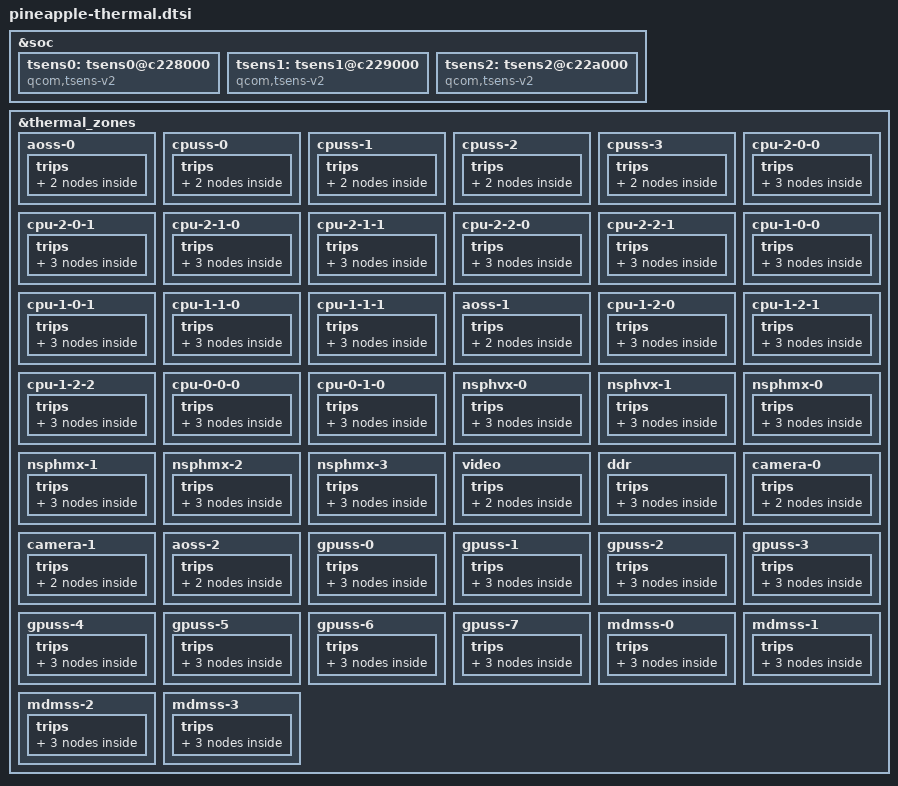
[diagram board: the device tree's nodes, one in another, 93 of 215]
#include <dt-bindings/thermal/thermal_qti.h>

&soc {
	tsens0: tsens0@c228000 {
		compatible = "qcom,tsens-v2";
		reg = <0x0c228000 0x1ff>, /* TM */
		      <0x0c222000 0x1ff>; /* SROT */
		#qcom,sensors = <15>;
		interrupts = <GIC_SPI 506 IRQ_TYPE_LEVEL_HIGH>,
			     <GIC_SPI 640 IRQ_TYPE_LEVEL_HIGH>;
		interrupt-names = "uplow","critical";
		#thermal-sensor-cells = <1>;
	};

	tsens1: tsens1@c229000 {
		compatible = "qcom,tsens-v2";
		reg = <0x0c229000 0x1ff>, /* TM */
		      <0x0c223000 0x1ff>; /* SROT */
		#qcom,sensors = <16>;
		interrupts = <GIC_SPI 507 IRQ_TYPE_LEVEL_HIGH>,
			     <GIC_SPI 641 IRQ_TYPE_LEVEL_HIGH>;
		interrupt-names = "uplow","critical";
		#thermal-sensor-cells = <1>;
	};

	tsens2: tsens2@c22a000 {
		compatible = "qcom,tsens-v2";
		reg = <0x0c22a000 0x1ff>, /* TM */
		      <0x0c224000 0x1ff>; /* SROT */
		#qcom,sensors = <13>;
		interrupts = <GIC_SPI 508 IRQ_TYPE_LEVEL_HIGH>,
			     <GIC_SPI 642 IRQ_TYPE_LEVEL_HIGH>;
		interrupt-names = "uplow","critical";
		#thermal-sensor-cells = <1>;
	};
};

&thermal_zones {
	aoss-0 {
		polling-delay-passive = <0>;
		polling-delay = <0>;
		thermal-sensors = <&tsens0 0>;
		trips {
			thermal-engine-config {
				temperature = <125000>;
				hysteresis = <1000>;
				type = "passive";
			};

			reset-mon-cfg {
				temperature = <115000>;
				hysteresis = <5000>;
				type = "passive";
			};
		};
	};

	cpuss-0 {
		polling-delay-passive = <0>;
		polling-delay = <0>;
		thermal-sensors = <&tsens0 1>;
		trips {
			thermal-engine-config {
				temperature = <125000>;
				hysteresis = <1000>;
				type = "passive";
			};

			reset-mon-cfg {
				temperature = <115000>;
				hysteresis = <5000>;
				type = "passive";
			};
		};
	};

	cpuss-1 {
		polling-delay-passive = <0>;
		polling-delay = <0>;
		thermal-sensors = <&tsens0 2>;
		trips {
			thermal-engine-config {
				temperature = <125000>;
				hysteresis = <1000>;
				type = "passive";
			};

			reset-mon-cfg {
				temperature = <115000>;
				hysteresis = <5000>;
				type = "passive";
			};
		};
	};

	cpuss-2 {
		polling-delay-passive = <0>;
		polling-delay = <0>;
		thermal-sensors = <&tsens0 3>;
		trips {
			thermal-engine-config {
				temperature = <125000>;
				hysteresis = <1000>;
				type = "passive";
			};

			reset-mon-cfg {
				temperature = <115000>;
				hysteresis = <5000>;
				type = "passive";
			};
		};
	};

	cpuss-3 {
		polling-delay-passive = <0>;
		polling-delay = <0>;
		thermal-sensors = <&tsens0 4>;
		trips {
			thermal-engine-config {
				temperature = <125000>;
				hysteresis = <1000>;
				type = "passive";
			};

			reset-mon-cfg {
				temperature = <115000>;
				hysteresis = <5000>;
				type = "passive";
			};
		};
	};

	cpu-2-0-0 {
		polling-delay-passive = <0>;
		polling-delay = <0>;
		thermal-sensors = <&tsens0 5>;
		trips {
			thermal-engine-config {
				temperature = <125000>;
				hysteresis = <1000>;
				type = "passive";
			};

			thermal-hal-config {
				temperature = <125000>;
				hysteresis = <1000>;
				type = "passive";
			};

			reset-mon-cfg {
				temperature = <115000>;
				hysteresis = <5000>;
				type = "passive";
			};
		};
	};

	cpu-2-0-1 {
		polling-delay-passive = <0>;
		polling-delay = <0>;
		thermal-sensors = <&tsens0 6>;
		trips {
			thermal-engine-config {
				temperature = <125000>;
				hysteresis = <1000>;
				type = "passive";
			};

			thermal-hal-config {
				temperature = <125000>;
				hysteresis = <1000>;
				type = "passive";
			};

			reset-mon-cfg {
				temperature = <115000>;
				hysteresis = <5000>;
				type = "passive";
			};
		};
	};

	cpu-2-1-0 {
		polling-delay-passive = <0>;
		polling-delay = <0>;
		thermal-sensors = <&tsens0 7>;
		trips {
			thermal-engine-config {
				temperature = <125000>;
				hysteresis = <1000>;
				type = "passive";
			};

			thermal-hal-config {
				temperature = <125000>;
				hysteresis = <1000>;
				type = "passive";
			};

			reset-mon-cfg {
				temperature = <115000>;
				hysteresis = <5000>;
				type = "passive";
			};
		};
	};

	cpu-2-1-1 {
		polling-delay-passive = <0>;
		polling-delay = <0>;
		thermal-sensors = <&tsens0 8>;
		trips {
			thermal-engine-config {
				temperature = <125000>;
				hysteresis = <1000>;
				type = "passive";
			};

			thermal-hal-config {
				temperature = <125000>;
				hysteresis = <1000>;
				type = "passive";
			};

			reset-mon-cfg {
				temperature = <115000>;
				hysteresis = <5000>;
				type = "passive";
			};
		};
	};

	cpu-2-2-0 {
		polling-delay-passive = <0>;
		polling-delay = <0>;
		thermal-sensors = <&tsens0 9>;
		trips {
			thermal-engine-config {
				temperature = <125000>;
				hysteresis = <1000>;
				type = "passive";
			};

			thermal-hal-config {
				temperature = <125000>;
				hysteresis = <1000>;
				type = "passive";
			};

			reset-mon-cfg {
				temperature = <115000>;
				hysteresis = <5000>;
				type = "passive";
			};
		};
	};

	cpu-2-2-1 {
		polling-delay-passive = <0>;
		polling-delay = <0>;
		thermal-sensors = <&tsens0 10>;
		trips {
			thermal-engine-config {
				temperature = <125000>;
				hysteresis = <1000>;
				type = "passive";
			};

			thermal-hal-config {
				temperature = <125000>;
				hysteresis = <1000>;
				type = "passive";
			};

			reset-mon-cfg {
				temperature = <115000>;
				hysteresis = <5000>;
				type = "passive";
			};
		};
	};

	cpu-1-0-0 {
		polling-delay-passive = <0>;
		polling-delay = <0>;
		thermal-sensors = <&tsens0 11>;
		trips {
			thermal-engine-config {
				temperature = <125000>;
				hysteresis = <1000>;
				type = "passive";
			};

			thermal-hal-config {
				temperature = <125000>;
				hysteresis = <1000>;
				type = "passive";
			};

			reset-mon-cfg {
				temperature = <115000>;
				hysteresis = <5000>;
				type = "passive";
			};
		};
	};

	cpu-1-0-1 {
		polling-delay-passive = <0>;
		polling-delay = <0>;
		thermal-sensors = <&tsens0 12>;
		trips {
			thermal-engine-config {
				temperature = <125000>;
				hysteresis = <1000>;
				type = "passive";
			};

			thermal-hal-config {
				temperature = <125000>;
				hysteresis = <1000>;
				type = "passive";
			};

			reset-mon-cfg {
				temperature = <115000>;
				hysteresis = <5000>;
				type = "passive";
			};
		};
	};

	cpu-1-1-0 {
		polling-delay-passive = <0>;
		polling-delay = <0>;
		thermal-sensors = <&tsens0 13>;
		trips {
			thermal-engine-config {
				temperature = <125000>;
				hysteresis = <1000>;
				type = "passive";
			};

			thermal-hal-config {
				temperature = <125000>;
				hysteresis = <1000>;
				type = "passive";
			};

			reset-mon-cfg {
				temperature = <115000>;
				hysteresis = <5000>;
				type = "passive";
			};
		};
	};

	cpu-1-1-1 {
		polling-delay-passive = <0>;
		polling-delay = <0>;
		thermal-sensors = <&tsens0 14>;
		trips {
			thermal-engine-config {
				temperature = <125000>;
				hysteresis = <1000>;
				type = "passive";
			};

			thermal-hal-config {
				temperature = <125000>;
				hysteresis = <1000>;
				type = "passive";
			};

			reset-mon-cfg {
				temperature = <115000>;
				hysteresis = <5000>;
				type = "passive";
			};
		};
	};

	aoss-1 {
		polling-delay-passive = <0>;
		polling-delay = <0>;
		thermal-sensors = <&tsens1 0>;
		trips {
			thermal-engine-config {
				temperature = <125000>;
				hysteresis = <1000>;
				type = "passive";
			};

			reset-mon-cfg {
				temperature = <115000>;
				hysteresis = <5000>;
				type = "passive";
			};
		};
	};

	cpu-1-2-0 {
		polling-delay-passive = <0>;
		polling-delay = <0>;
		thermal-sensors = <&tsens1 1>;
		trips {
			thermal-engine-config {
				temperature = <125000>;
				hysteresis = <1000>;
				type = "passive";
			};

			thermal-hal-config {
				temperature = <125000>;
				hysteresis = <1000>;
				type = "passive";
			};

			reset-mon-cfg {
				temperature = <115000>;
				hysteresis = <5000>;
				type = "passive";
			};
		};
	};

	cpu-1-2-1 {
		polling-delay-passive = <0>;
		polling-delay = <0>;
		thermal-sensors = <&tsens1 2>;
		trips {
			thermal-engine-config {
				temperature = <125000>;
				hysteresis = <1000>;
				type = "passive";
			};

			thermal-hal-config {
				temperature = <125000>;
				hysteresis = <1000>;
				type = "passive";
			};

			reset-mon-cfg {
				temperature = <115000>;
				hysteresis = <5000>;
				type = "passive";
			};
		};
	};

	cpu-1-2-2 {
		polling-delay-passive = <0>;
		polling-delay = <0>;
		thermal-sensors = <&tsens1 3>;
		trips {
			thermal-engine-config {
				temperature = <125000>;
				hysteresis = <1000>;
				type = "passive";
			};

			thermal-hal-config {
				temperature = <125000>;
				hysteresis = <1000>;
				type = "passive";
			};

			reset-mon-cfg {
				temperature = <115000>;
				hysteresis = <5000>;
				type = "passive";
			};
		};
	};

	cpu-0-0-0 {
		polling-delay-passive = <0>;
		polling-delay = <0>;
		thermal-sensors = <&tsens1 4>;
		trips {
			thermal-engine-config {
				temperature = <125000>;
				hysteresis = <1000>;
				type = "passive";
			};

			thermal-hal-config {
				temperature = <125000>;
				hysteresis = <1000>;
				type = "passive";
			};

			reset-mon-cfg {
				temperature = <115000>;
				hysteresis = <5000>;
				type = "passive";
			};
		};
	};

	cpu-0-1-0 {
		polling-delay-passive = <0>;
		polling-delay = <0>;
		thermal-sensors = <&tsens1 5>;
		trips {
			thermal-engine-config {
				temperature = <125000>;
				hysteresis = <1000>;
				type = "passive";
			};

			thermal-hal-config {
				temperature = <125000>;
				hysteresis = <1000>;
				type = "passive";
			};

			reset-mon-cfg {
				temperature = <115000>;
				hysteresis = <5000>;
				type = "passive";
			};
		};
	};

	nsphvx-0 {
		polling-delay-passive = <0>;
		polling-delay = <0>;
		thermal-sensors = <&tsens1 6>;
		trips {
			thermal-engine-config {
				temperature = <125000>;
				hysteresis = <1000>;
				type = "passive";
			};

			thermal-hal-config {
				temperature = <125000>;
				hysteresis = <1000>;
				type = "passive";
			};

			reset-mon-cfg {
				temperature = <115000>;
				hysteresis = <5000>;
				type = "passive";
			};
		};
	};

	nsphvx-1 {
		polling-delay-passive = <0>;
		polling-delay = <0>;
		thermal-sensors = <&tsens1 7>;
		trips {
			thermal-engine-config {
				temperature = <125000>;
				hysteresis = <1000>;
				type = "passive";
			};

			thermal-hal-config {
				temperature = <125000>;
				hysteresis = <1000>;
				type = "passive";
			};

			reset-mon-cfg {
				temperature = <115000>;
				hysteresis = <5000>;
				type = "passive";
			};
		};
	};

	nsphmx-0 {
		polling-delay-passive = <0>;
		polling-delay = <0>;
		thermal-sensors = <&tsens1 8>;
		trips {
			thermal-engine-config {
				temperature = <125000>;
				hysteresis = <1000>;
				type = "passive";
			};

			thermal-hal-config {
				temperature = <125000>;
				hysteresis = <1000>;
				type = "passive";
			};

			reset-mon-cfg {
				temperature = <115000>;
				hysteresis = <5000>;
				type = "passive";
			};
		};
	};

	nsphmx-1 {
		polling-delay-passive = <0>;
		polling-delay = <0>;
		thermal-sensors = <&tsens1 9>;
		trips {
			thermal-engine-config {
				temperature = <125000>;
				hysteresis = <1000>;
				type = "passive";
			};

			thermal-hal-config {
				temperature = <125000>;
				hysteresis = <1000>;
				type = "passive";
			};

			reset-mon-cfg {
				temperature = <115000>;
				hysteresis = <5000>;
				type = "passive";
			};
		};
	};

	nsphmx-2 {
		polling-delay-passive = <0>;
		polling-delay = <0>;
		thermal-sensors = <&tsens1 10>;
		trips {
			thermal-engine-config {
				temperature = <125000>;
				hysteresis = <1000>;
				type = "passive";
			};

			thermal-hal-config {
				temperature = <125000>;
				hysteresis = <1000>;
				type = "passive";
			};

			reset-mon-cfg {
				temperature = <115000>;
				hysteresis = <5000>;
				type = "passive";
			};
		};
	};

	nsphmx-3 {
		polling-delay-passive = <0>;
		polling-delay = <0>;
		thermal-sensors = <&tsens1 11>;
		trips {
			thermal-engine-config {
				temperature = <125000>;
				hysteresis = <1000>;
				type = "passive";
			};

			thermal-hal-config {
				temperature = <125000>;
				hysteresis = <1000>;
				type = "passive";
			};

			reset-mon-cfg {
				temperature = <115000>;
				hysteresis = <5000>;
				type = "passive";
			};
		};
	};

	video {
		polling-delay-passive = <0>;
		polling-delay = <0>;
		thermal-sensors = <&tsens1 12>;
		trips {
			thermal-engine-config {
				temperature = <125000>;
				hysteresis = <1000>;
				type = "passive";
			};

			reset-mon-cfg {
				temperature = <115000>;
				hysteresis = <5000>;
				type = "passive";
			};
		};
	};

	ddr {
		polling-delay-passive = <0>;
		polling-delay = <0>;
		thermal-sensors = <&tsens1 13>;
		trips {
			thermal-engine-config {
				temperature = <125000>;
				hysteresis = <1000>;
				type = "passive";
			};

			ddr_config0: ddr0-config {
				temperature = <90000>;
				hysteresis = <5000>;
				type = "passive";
			};

			reset-mon-cfg {
				temperature = <115000>;
				hysteresis = <5000>;
				type = "passive";
			};
		};
	};

	camera-0 {
		polling-delay-passive = <0>;
		polling-delay = <0>;
		thermal-sensors = <&tsens1 14>;
		trips {
			thermal-engine-config {
				temperature = <125000>;
				hysteresis = <1000>;
				type = "passive";
			};

			reset-mon-cfg {
				temperature = <115000>;
				hysteresis = <5000>;
				type = "passive";
			};
		};
	};

	camera-1 {
		polling-delay-passive = <0>;
		polling-delay = <0>;
		thermal-sensors = <&tsens1 15>;
		trips {
			thermal-engine-config {
				temperature = <125000>;
				hysteresis = <1000>;
				type = "passive";
			};

			reset-mon-cfg {
				temperature = <115000>;
				hysteresis = <5000>;
				type = "passive";
			};
		};
	};

	aoss-2 {
		polling-delay-passive = <0>;
		polling-delay = <0>;
		thermal-sensors = <&tsens2 0>;
		trips {
			thermal-engine-config {
				temperature = <125000>;
				hysteresis = <1000>;
				type = "passive";
			};

			reset-mon-cfg {
				temperature = <115000>;
				hysteresis = <5000>;
				type = "passive";
			};
		};
	};

	gpuss-0 {
		polling-delay-passive = <0>;
		polling-delay = <0>;
		thermal-sensors = <&tsens1 1>;
		trips {
			thermal-engine-config {
				temperature = <125000>;
				hysteresis = <1000>;
				type = "passive";
			};

			thermal-hal-config {
				temperature = <125000>;
				hysteresis = <1000>;
				type = "passive";
			};

			reset-mon-cfg {
				temperature = <115000>;
				hysteresis = <5000>;
				type = "passive";
			};
		};
	};

	gpuss-1 {
		polling-delay-passive = <0>;
		polling-delay = <0>;
		thermal-sensors = <&tsens1 2>;
		trips {
			thermal-engine-config {
				temperature = <125000>;
				hysteresis = <1000>;
				type = "passive";
			};

			thermal-hal-config {
				temperature = <125000>;
				hysteresis = <1000>;
				type = "passive";
			};

			reset-mon-cfg {
				temperature = <115000>;
				hysteresis = <5000>;
				type = "passive";
			};
		};
	};

	gpuss-2 {
		polling-delay-passive = <0>;
		polling-delay = <0>;
		thermal-sensors = <&tsens1 3>;
		trips {
			thermal-engine-config {
				temperature = <125000>;
				hysteresis = <1000>;
				type = "passive";
			};

			thermal-hal-config {
				temperature = <125000>;
				hysteresis = <1000>;
				type = "passive";
			};

			reset-mon-cfg {
				temperature = <115000>;
				hysteresis = <5000>;
				type = "passive";
			};
		};
	};

	gpuss-3 {
		polling-delay-passive = <0>;
		polling-delay = <0>;
		thermal-sensors = <&tsens1 4>;
		trips {
			thermal-engine-config {
				temperature = <125000>;
				hysteresis = <1000>;
				type = "passive";
			};

			thermal-hal-config {
				temperature = <125000>;
				hysteresis = <1000>;
				type = "passive";
			};

			reset-mon-cfg {
				temperature = <115000>;
				hysteresis = <5000>;
				type = "passive";
			};
		};
	};

	gpuss-4 {
		polling-delay-passive = <0>;
		polling-delay = <0>;
		thermal-sensors = <&tsens1 5>;
		trips {
			thermal-engine-config {
				temperature = <125000>;
				hysteresis = <1000>;
				type = "passive";
			};

			thermal-hal-config {
				temperature = <125000>;
				hysteresis = <1000>;
				type = "passive";
			};

			reset-mon-cfg {
				temperature = <115000>;
				hysteresis = <5000>;
				type = "passive";
			};
		};
	};

	gpuss-5 {
		polling-delay-passive = <0>;
		polling-delay = <0>;
		thermal-sensors = <&tsens1 6>;
		trips {
			thermal-engine-config {
				temperature = <125000>;
				hysteresis = <1000>;
				type = "passive";
			};

			thermal-hal-config {
				temperature = <125000>;
				hysteresis = <1000>;
				type = "passive";
			};

			reset-mon-cfg {
				temperature = <115000>;
				hysteresis = <5000>;
				type = "passive";
			};
		};
	};

	gpuss-6 {
		polling-delay-passive = <0>;
		polling-delay = <0>;
		thermal-sensors = <&tsens1 7>;
		trips {
			thermal-engine-config {
				temperature = <125000>;
				hysteresis = <1000>;
				type = "passive";
			};

			thermal-hal-config {
				temperature = <125000>;
				hysteresis = <1000>;
				type = "passive";
			};

			reset-mon-cfg {
				temperature = <115000>;
				hysteresis = <5000>;
				type = "passive";
			};
		};
	};

	gpuss-7 {
		polling-delay-passive = <0>;
		polling-delay = <0>;
		thermal-sensors = <&tsens1 8>;
		trips {
			thermal-engine-config {
				temperature = <125000>;
				hysteresis = <1000>;
				type = "passive";
			};

			thermal-hal-config {
				temperature = <125000>;
				hysteresis = <1000>;
				type = "passive";
			};

			reset-mon-cfg {
				temperature = <115000>;
				hysteresis = <5000>;
				type = "passive";
			};
		};
	};

	mdmss-0 {
		polling-delay-passive = <0>;
		polling-delay = <0>;
		thermal-sensors = <&tsens1 9>;
		trips {
			thermal-engine-config {
				temperature = <125000>;
				hysteresis = <1000>;
				type = "passive";
			};

			thermal-hal-config {
				temperature = <125000>;
				hysteresis = <1000>;
				type = "passive";
			};

			reset-mon-cfg {
				temperature = <115000>;
				hysteresis = <5000>;
				type = "passive";
			};
		};
	};

	mdmss-1 {
		polling-delay-passive = <0>;
		polling-delay = <0>;
		thermal-sensors = <&tsens1 10>;
		trips {
			thermal-engine-config {
				temperature = <125000>;
				hysteresis = <1000>;
				type = "passive";
			};

			thermal-hal-config {
				temperature = <125000>;
				hysteresis = <1000>;
				type = "passive";
			};

			reset-mon-cfg {
				temperature = <115000>;
				hysteresis = <5000>;
				type = "passive";
			};
		};
	};

	mdmss-2 {
		polling-delay-passive = <0>;
		polling-delay = <0>;
		thermal-sensors = <&tsens1 11>;
		trips {
			thermal-engine-config {
				temperature = <125000>;
				hysteresis = <1000>;
				type = "passive";
			};

			thermal-hal-config {
				temperature = <125000>;
				hysteresis = <1000>;
				type = "passive";
			};

			reset-mon-cfg {
				temperature = <115000>;
				hysteresis = <5000>;
				type = "passive";
			};
		};
	};

	mdmss-3 {
		polling-delay-passive = <0>;
		polling-delay = <0>;
		thermal-sensors = <&tsens1 12>;
		trips {
			thermal-engine-config {
				temperature = <125000>;
				hysteresis = <1000>;
				type = "passive";
			};

			thermal-hal-config {
				temperature = <125000>;
				hysteresis = <1000>;
				type = "passive";
			};

			reset-mon-cfg {
				temperature = <115000>;
				hysteresis = <5000>;
				type = "passive";
			};
		};
	};
};
